# ATtiny26 device description
Architecture: AVR8; Family: tinyAVR
Registers are 8-bit, access not given, no defined reset value unless marked. A register's access mark holds for its fields unless they carry their own. Offsets are from the block's base; [hi:lo] are bit positions; 'fields as' and 'values as' point back to an identical list.

## USI — Universal Serial Interface
Instances: USI 0x00
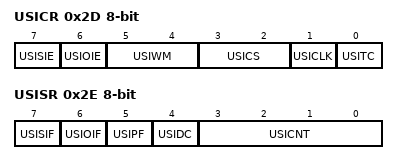
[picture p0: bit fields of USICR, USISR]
0x2D USICR — USI Control Register
  [7] USISIE — Start Condition Interrupt Enable
  [6] USIOIE — Counter Overflow Interrupt Enable
  [5:4] USIWM — USI Wire Mode Bits
    0=NORMAL_OPERATION; 1=THREE_WIRE_MODE; 2=TWO_WIRE_MODE; 3=TWO_WIRE_MODE_HELD_LOW
  [3:2] USICS — USI Clock Source Select Bits
  [1] USICLK — Clock Strobe
  [0] USITC — Toggle Clock Port Pin
0x2E USISR — USI Status Register
  [7] USISIF — Start Condition Interrupt Flag
  [6] USIOIF — Counter Overflow Interrupt Flag
  [5] USIPF — Stop Condition Flag
  [4] USIDC — Data Output Collision
  [3:0] USICNT — USI Counter Value Bits
0x2F USIDR — USI Data Register

## PORTA — I/O Port
Instances: PORTA 0x00
0x39 PINA — Port A Input Pins
0x3A DDRA — Port A Data Direction Register
0x3B PORTA — Port A Data Register

## PORTB — I/O Port
Instances: PORTB 0x00
0x36 PINB — Port B Input Pins
0x37 DDRB — Port B Data Direction Register
0x38 PORTB — Port B Data Register

## EEPROM
Instances: EEPROM 0x00
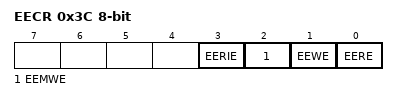
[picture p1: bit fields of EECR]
0x3C EECR — EEPROM Control Register
  [3] EERIE — EEProm Ready Interrupt Enable
  [2] EEMWE — EEPROM Master Write Enable
  [1] EEWE — EEPROM Write Enable
  [0] EERE — EEPROM Read Enable
0x3D EEDR — EEPROM Data Register
0x3E EEAR bits used 6:0 — EEPROM Read/Write Access

## WDT — Watchdog Timer
Instances: WDT 0x00
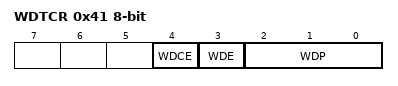
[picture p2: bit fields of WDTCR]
0x41 WDTCR — Watchdog Timer Control Register
  [4] WDCE — Watchdog Change Enable
  [3] WDE — Watch Dog Enable
  [2:0] WDP — Watch Dog Timer Prescaler bits
    0=OSCILLATOR_CYCLES_16K; 1=OSCILLATOR_CYCLES_32K; 2=OSCILLATOR_CYCLES_64K; 3=OSCILLATOR_CYCLES_128K; 4=OSCILLATOR_CYCLES_256K; 5=OSCILLATOR_CYCLES_512K; 6=OSCILLATOR_CYCLES_1024K; 7=OSCILLATOR_CYCLES_2048K

## CPU — CPU Registers
Instances: CPU 0x00
0x51 OSCCAL — Status Register
  [7:0] OSCCAL — Oscillator Calibration
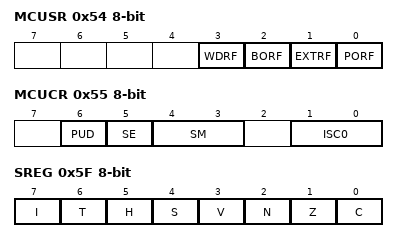
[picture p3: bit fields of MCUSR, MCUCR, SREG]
0x54 MCUSR — MCU Status register
  [3] WDRF — Watchdog Reset Flag
  [2] BORF — Brown-out Reset Flag
  [1] EXTRF — External Reset Flag
  [0] PORF — Power-On Reset Flag
0x55 MCUCR — MCU Control Register
  [6] PUD — Pull-up Disable
  [5] SE — Sleep Enable
  [4:3] SM — Sleep Mode Select Bits
    0=IDLE; 1=ADC (ADC Noise Reduction (If Available)); 2=PDOWN (Power Down); 3=STDBY (Standby)
  [1:0] ISC0 — Interrupt Sense Control 0 bits
    0=LOW_LEVEL_OF_INTX; 1=ANY_LOGICAL_CHANGE_IN_INTX; 2=FALLING_EDGE_OF_INTX; 3=RISING_EDGE_OF_INTX
0x5D SP — Stack Pointer
0x5F SREG — Status Register
  [7] I — Global Interrupt Enable
  [6] T — Bit Copy Storage
  [5] H — Half Carry Flag
  [4] S — Sign Bit
  [3] V — Two's Complement Overflow Flag
  [2] N — Negative Flag
  [1] Z — Zero Flag
  [0] C — Carry Flag
Value list OSCCAL_VALUE_ADDRESSES: 0=1_0_MHz; 1=2_0_MHz; 2=4_0_MHz; 3=8_0_MHz

## TC0 (TC8 module) — Timer/Counter, 8-bit
Instances: TC0 0x00
0x52 TCNT0 — Timer Counter 0
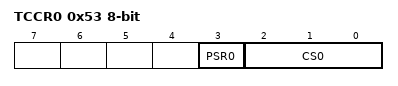
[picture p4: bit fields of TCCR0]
0x53 TCCR0 — Timer/Counter0 Control Register
  [3] PSR0 — Prescaler Reset Timer/Counter0
  [2:0] CS0 — Clock Select0 bits
    0=NO_CLOCK_SOURCE_STOPPED; 1=RUNNING_NO_PRESCALING; 2=RUNNING_CLK_8; 3=RUNNING_CLK_64; 4=RUNNING_CLK_256; 5=RUNNING_CLK_1024; 6=RUNNING_EXTCLK_TN_FALLING_EDGE; 7=RUNNING_EXTCLK_TN_RISING_EDGE
0x58 TIFR — Timer/Counter Interrupt Flag register
  [1] TOV0 — Timer/Counter0 Overflow Flag
0x59 TIMSK — Timer/Counter Interrupt Mask Register
  [1] TOIE0 — Timer/Counter0 Overflow Interrupt Enable

## TC1 (TC8 module) — Timer/Counter, 8-bit
Instances: TC1 0x00
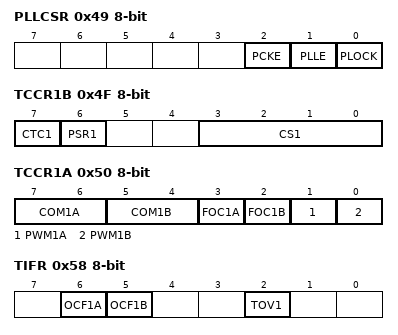
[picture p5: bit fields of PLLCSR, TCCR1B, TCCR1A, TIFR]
0x49 PLLCSR — PLL Control and Status Register
  [2] PCKE — PCK Enable
  [1] PLLE — PLL Enable
  [0] PLOCK — PLL Lock Detector
0x4B OCR1C — Output Compare Register
0x4C OCR1B — Output Compare Register
0x4D OCR1A — Output Compare Register
0x4E TCNT1 — Timer/Counter Register
0x4F TCCR1B — Timer/Counter Control Register B
  [7] CTC1 — Clear Timer/Counter on Compare Match
  [6] PSR1 — Prescaler Reset Timer/Counter1
  [3:0] CS1 — Clock Select Bits
    0=NO_CLOCK_SOURCE_STOPPED; 1=RUNNING_NO_PRESCALING; 2=RUNNING_CLK_2; 3=RUNNING_CLK_4; 4=RUNNING_CLK_8; 5=RUNNING_CLK_16; 6=RUNNING_CLK_32; 7=RUNNING_CLK_64; 8=RUNNING_CLK_128; 9=RUNNING_CLK_256; 10=RUNNING_CLK_512; 11=RUNNING_CLK_1024; 12=RUNNING_CLK_2048; 13=RUNNING_CLK_4096; 14=RUNNING_CLK_8192; 15=RUNNING_CLK_16384
0x50 TCCR1A — Timer/Counter Control Register A
  [7:6] COM1A — Comparator A Output Mode Bits
    0=DISCONNECTED_FROM_OCN_PWMN; 1=TOGGLE_OCN_PWMN_OUTPUT_LINE; 2=CLEAR_OCN_PWMN_OUTPUT_LINE; 3=SET_OCN_PWMN_OUTPUT_LINE
  [5:4] COM1B — Comparator B Output Mode Bits
    values as COM1A
  [3] FOC1A — Force Output Compare Match 1A
  [2] FOC1B — Force Output Compare Match 1B
  [1] PWM1A — Pulse Width Modulator A Enable
  [0] PWM1B — Pulse Width Modulator B Enable
0x58 TIFR — Timer/Counter Interrupt Flag Register
  [6] OCF1A — Timer/Counter1 Output Compare Flag 1A
  [5] OCF1B — Timer/Counter1 Output Compare Flag 1B
  [2] TOV1 — Timer/Counter1 Overflow Flag
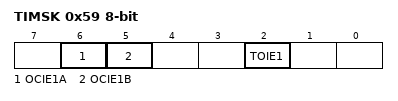
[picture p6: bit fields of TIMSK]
0x59 TIMSK — Timer/Counter Interrupt Mask Register
  [6] OCIE1A — Timer/Counter1 Output Compare Interrupt Enable
  [5] OCIE1B — Timer/Counter1 Output Compare Interrupt Enable
  [2] TOIE1 — Timer/Counter1 Overflow Interrupt Enable

## EXINT — External Interrupts
Instances: EXINT 0x00
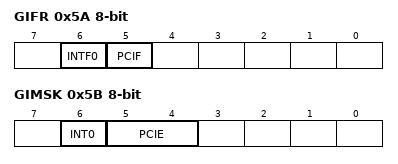
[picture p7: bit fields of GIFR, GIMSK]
0x5A GIFR — General Interrupt Flag register
  [6] INTF0 — External Interrupt Flag 0
  [5] PCIF — Pin Change Interrupt Flag
0x5B GIMSK — General Interrupt Mask Register
  [6] INT0 — External Interrupt Request 0 Enable
  [5:4] PCIE — Pin Change Interrupt Enables
